VERSION ""

NS_ :

BS_:
BU_:
BO_ 792 Steering_Wheel: 8 Vector__XXX

BO_ 133 GearStatus: 8 Vector__XXX
   SG_ GearPosition : 15|8@0+ (1,0) [0|1] "" Vector__XXX
   SG_ GearStatusSpeed : 39|16@0+ (0.5,0) [0|1] "" Vector__XXX

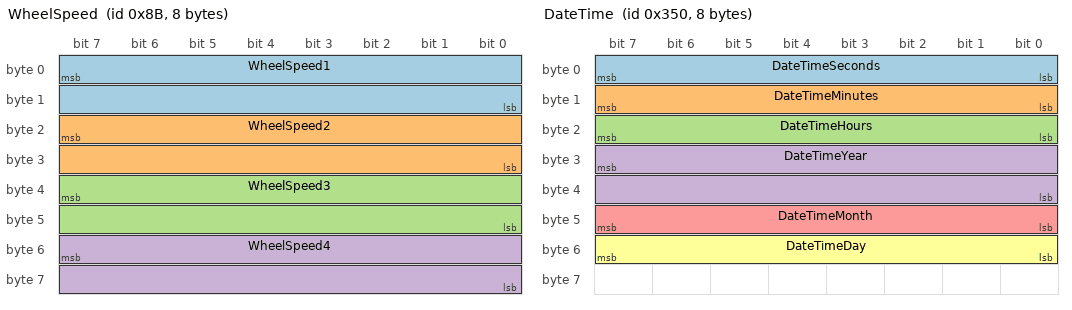
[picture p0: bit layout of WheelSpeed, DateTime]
BO_ 139 WheelSpeed: 8 Vector__XXX
   SG_ WheelSpeed1 : 7|16@0+ (1,0) [0|1] "" Vector__XXX
   SG_ WheelSpeed2 : 23|16@0+ (1,0) [0|1] "" Vector__XXX
   SG_ WheelSpeed3 : 39|16@0+ (1,0) [0|1] "" Vector__XXX
   SG_ WheelSpeed4 : 55|16@0+ (1,0) [0|1] "" Vector__XXX

BO_ 122 IgnitionSwitch: 4 Vector__XXX
   SG_ IgnitionSwitchPos : 15|8@0+ (1,0) [0|1] "" Vector__XXX

BO_ 1100 Config6: 8 Vector__XXX
   SG_ Config6 : 7|64@0+ (1,0) [0|1] "" Vector__XXX

BO_ 1098 Config5: 8 Vector__XXX
   SG_ Config5 : 7|64@0+ (1,0) [0|1] "" Vector__XXX

BO_ 992 VIN: 8 Vector__XXX
   SG_ VIN : 15|64@4- (1,0) [0|1] "" Vector__XXX
   SG_ VIN_MsgNo : 7|8@0+ (1,0) [0|1] "" Vector__XXX

BO_ 881 SwayBar: 8 Vector__XXX
   SG_ SwayBar : 1|2@0+ (1,0) [0|1] "" Vector__XXX

BO_ 848 DateTime: 8 Vector__XXX
   SG_ DateTimeSeconds : 7|8@0+ (1,0) [0|1] "" Vector__XXX
   SG_ DateTimeMinutes : 15|8@0+ (1,0) [0|1] "" Vector__XXX
   SG_ DateTimeHours : 23|8@0+ (1,0) [0|1] "" Vector__XXX
   SG_ DateTimeYear : 31|16@0+ (1,0) [0|1] "" Vector__XXX
   SG_ DateTimeMonth : 47|8@0+ (1,0) [0|1] "" Vector__XXX
   SG_ DateTimeDay : 55|8@0+ (1,0) [0|1] "" Vector__XXX

BO_ 808 MusicInfo: 8 Vector__XXX

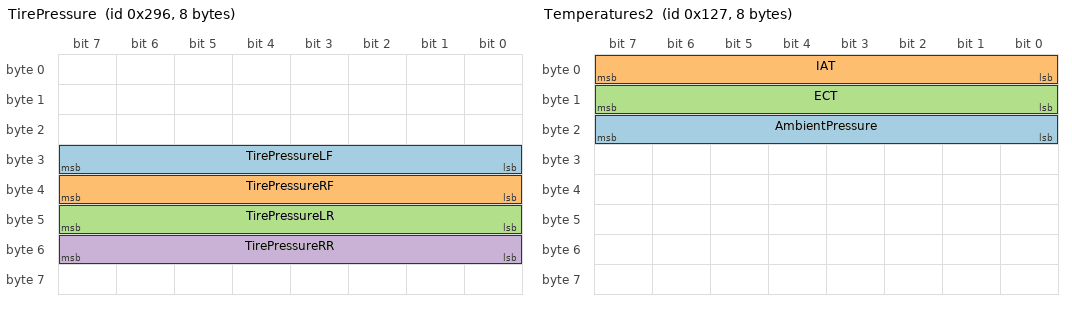
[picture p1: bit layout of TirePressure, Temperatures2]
BO_ 662 TirePressure: 8 Vector__XXX
   SG_ TirePressureLF : 31|8@0+ (1,0) [0|1] "psi" Vector__XXX
   SG_ TirePressureRF : 39|8@0+ (1,0) [0|1] "psi" Vector__XXX
   SG_ TirePressureLR : 47|8@0+ (1,0) [0|1] "psi" Vector__XXX
   SG_ TirePressureRR : 55|8@0+ (1,0) [0|1] "psi" Vector__XXX

BO_ 295 Temperatures2: 8 Vector__XXX
   SG_ AmbientPressure : 23|8@0+ (1,0) [0|1] "kPa" Vector__XXX
   SG_ IAT : 7|8@0+ (1,-40) [0|1] "C" Vector__XXX
   SG_ ECT : 15|8@0+ (1,-40) [0|1] "C" Vector__XXX

BO_ 2147483795 GearPosition: 8 Vector__XXX
   SG_ GearPositionSig278 : 23|8@4- (1,0) [0|1] "" Vector__XXX

BO_ 2147484031 GPSSpeed: 8 Vector__XXX
   SG_ GPSSpeed : 55|16@0+ (1,0) [0|1] "" Vector__XXX

BO_ 2147483683 SteeringWheel: 8 Vector__XXX
   SG_ SteeringWheelAngle : 7|16@0+ (1,-4096) [0|1] "" Vector__XXX
   SG_ SteeringWheelTorque : 23|16@0+ (1,-4096) [0|1] "" Vector__XXX

BO_ 2147484556 DateTime2: 8 Vector__XXX
   SG_ DateTime2Seconds : 63|8@0+ (1,0) [0|1] "" Vector__XXX

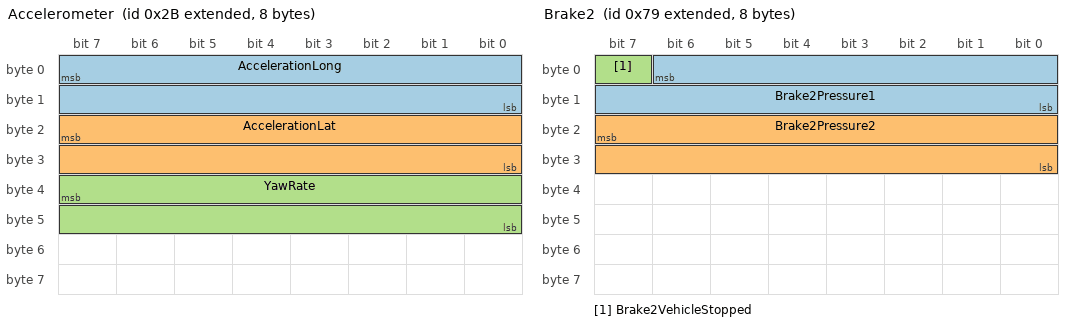
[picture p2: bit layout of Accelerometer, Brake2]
BO_ 2147483691 Accelerometer: 8 Vector__XXX
   SG_ AccelerationLong : 7|16@0+ (1,-2048) [0|1] "" Vector__XXX
   SG_ AccelerationLat : 23|16@0+ (1,-2048) [0|1] "" Vector__XXX
   SG_ YawRate : 39|16@0+ (1,-2048) [0|1] "" Vector__XXX

BO_ 2147483783 Brake: 8 Vector__XXX
   SG_ BrakePressure : 7|16@0+ (1,0) [0|1] "" Vector__XXX

BO_ 2147483769 Brake2: 8 Vector__XXX
   SG_ Brake2Pressure1 : 6|15@0+ (1,0) [0|1] "" Vector__XXX
   SG_ Brake2Pressure2 : 23|16@0+ (1,0) [0|1] "" Vector__XXX
   SG_ Brake2VehicleStopped : 7|1@0+ (1,0) [0|1] "" Vector__XXX

BO_ 2147483779 Speed1: 8 Vector__XXX
   SG_ Speed1Speed : 37|14@0+ (0.5,0) [0|1] "kph" Vector__XXX

BO_ 2147483687 Unknown027: 8 Vector__XXX
   SG_ PossibleMAFFreq : 3|12@0+ (1,0) [0|1] "" Vector__XXX
   SG_ Unknown027Sig3277 : 23|16@0+ (1,-1900) [0|1] "" Vector__XXX

BO_ 2147483793 Constant: 8 Vector__XXX

CM_ SG_ 2147483691 AccelerationLong "Initially_F8_00";
BA_DEF_ BO_ "GenMsgBackgroundColor" STRING ;
BA_DEF_ BO_ "GenMsgForegroundColor" STRING ;
BA_DEF_ BO_ "filterlabeling" INT 0 0;
BA_DEF_ BO_ "filterlabeling" INT 0 0;
BA_DEF_ BO_ "filterlabeling" INT 0 0;
BA_DEF_ BO_ "filterlabeling" INT 0 0;
BA_DEF_ BO_ "filterlabeling" INT 0 0;
BA_DEF_ BO_ "filterlabeling" INT 0 0;
BA_DEF_ BO_ "filterlabeling" INT 0 0;
BA_DEF_ BO_ "filterlabeling" INT 0 0;
BA_DEF_ BO_ "filterlabeling" INT 0 0;
BA_DEF_ BO_ "filterlabeling" INT 0 0;
BA_DEF_ BO_ "filterlabeling" INT 0 0;
BA_DEF_ BO_ "filterlabeling" INT 0 0;
BA_DEF_ BO_ "filterlabeling" INT 0 0;
BA_DEF_ BO_ "filterlabeling" INT 0 0;
BA_DEF_ BO_ "filterlabeling" INT 0 0;
BA_DEF_DEF_ "GenMsgBackgroundColor" "#ffffff";
BA_DEF_DEF_ "GenMsgForegroundColor" "#000000";
BA_DEF_DEF_ "filterlabeling" 1;
BA_DEF_DEF_ "filterlabeling" 1;
VAL_ 881 SwayBar 0 "Disconnected" 1 "Connected" 2 "In_Progress";
